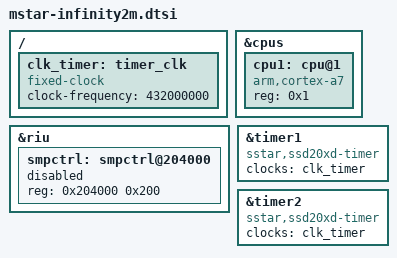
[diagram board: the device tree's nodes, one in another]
// SPDX-License-Identifier: GPL-2.0-or-later
/*
 * Copyright (c) 2020 thingy.jp.
 * Author: Daniel Palmer <daniel@thingy.jp>
 */

#include "mstar-infinity.dtsi"

/ {
	clk_timer: timer_clk {
		#clock-cells = <0>;
		compatible = "fixed-clock";
		clock-frequency = <432000000>;
	};
};

&cpus {
	cpu1: cpu@1 {
		device_type = "cpu";
		compatible = "arm,cortex-a7";
		reg = <0x1>;
	};
};

&riu {
	smpctrl: smpctrl@204000 {
		reg = <0x204000 0x200>;
		status = "disabled";
	};
};

&timer1 {
	compatible = "sstar,ssd20xd-timer";
	clocks = <&clk_timer>;
};

&timer2 {
	compatible = "sstar,ssd20xd-timer";
	clocks = <&clk_timer>;
};
